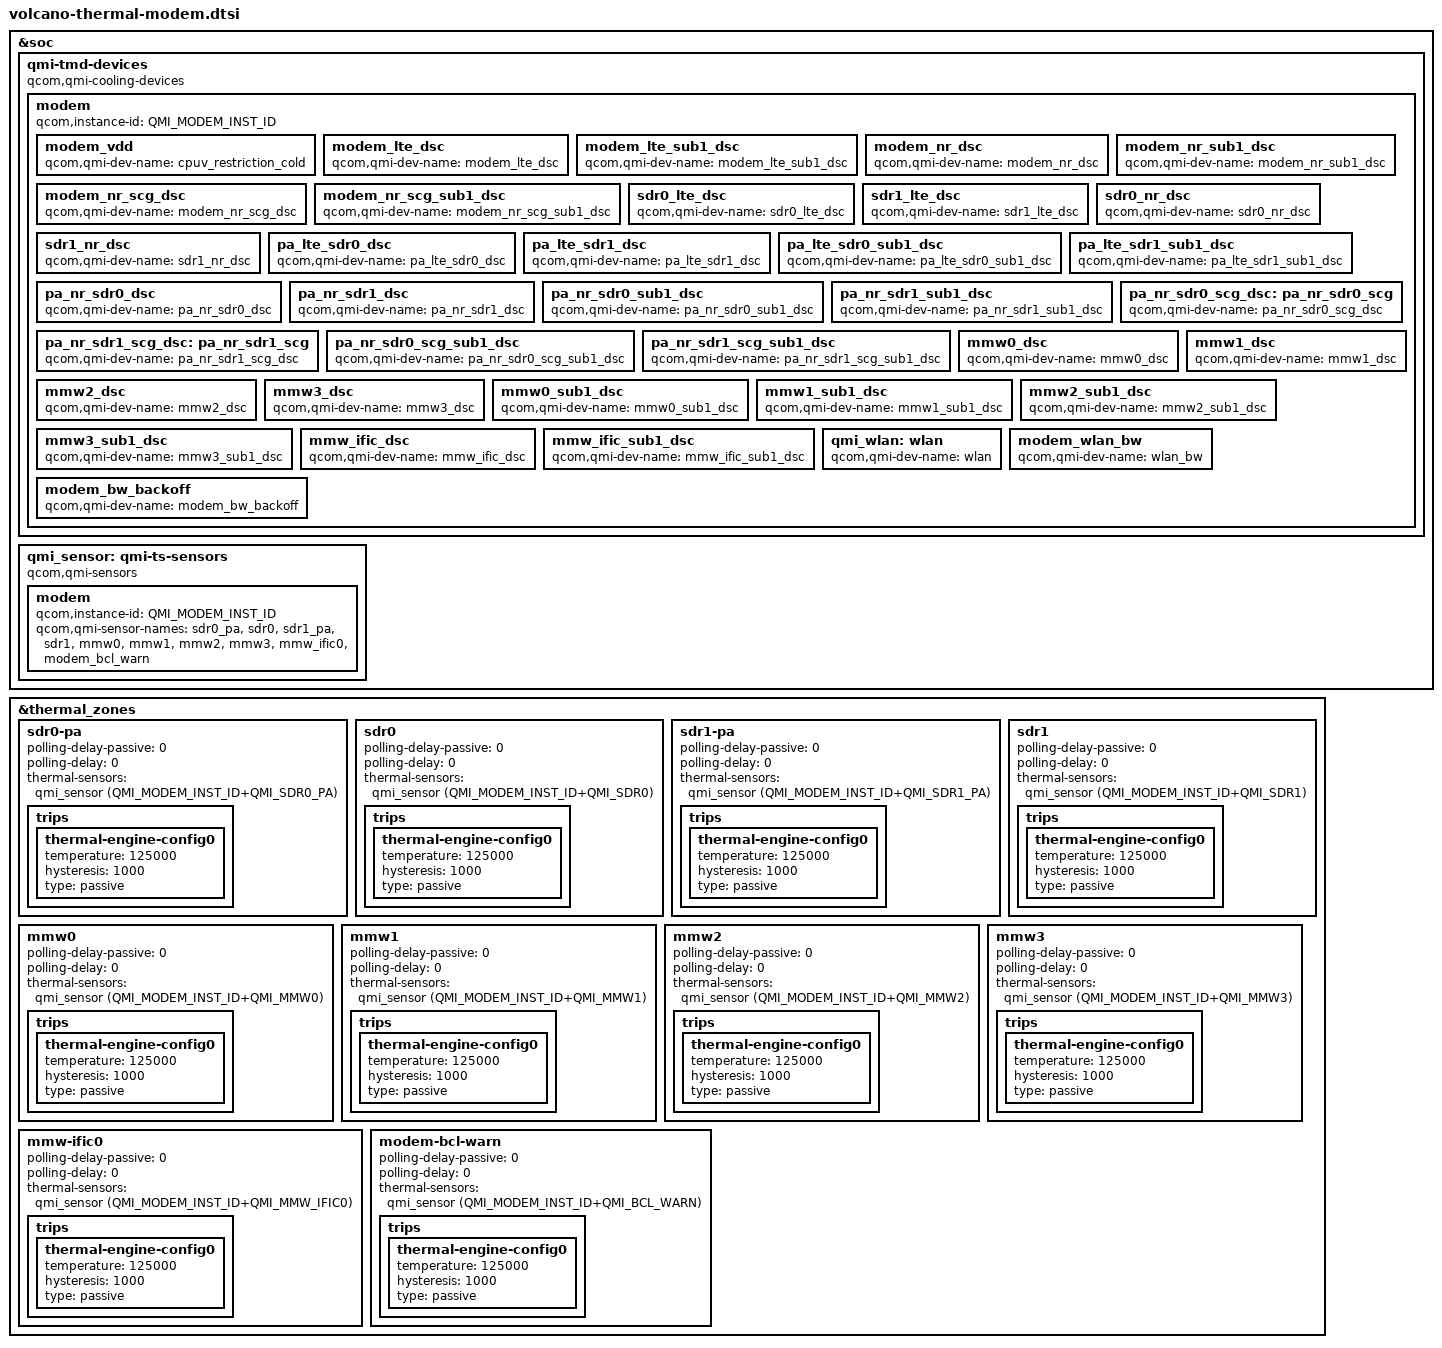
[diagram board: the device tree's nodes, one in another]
#include <dt-bindings/thermal/thermal_qti.h>

&soc {
	qmi-tmd-devices {
	    compatible = "qcom,qmi-cooling-devices";

	    modem {
			qcom,instance-id = <QMI_MODEM_INST_ID>;

			modem_vdd: modem_vdd {
				qcom,qmi-dev-name = "cpuv_restriction_cold";
				#cooling-cells = <2>;
			};

			modem_lte_dsc: modem_lte_dsc {
			    qcom,qmi-dev-name = "modem_lte_dsc";
			    #cooling-cells = <2>;
			};

			modem_lte_sub1_dsc: modem_lte_sub1_dsc {
				qcom,qmi-dev-name = "modem_lte_sub1_dsc";
				#cooling-cells = <2>;
			};

			modem_nr_dsc: modem_nr_dsc {
				qcom,qmi-dev-name = "modem_nr_dsc";
				#cooling-cells = <2>;
			};

			modem_nr_sub1_dsc: modem_nr_sub1_dsc {
				qcom,qmi-dev-name = "modem_nr_sub1_dsc";
				#cooling-cells = <2>;
			};

			modem_nr_scg_dsc: modem_nr_scg_dsc {
				qcom,qmi-dev-name = "modem_nr_scg_dsc";
				#cooling-cells = <2>;
			};

			modem_nr_scg_sub1_dsc: modem_nr_scg_sub1_dsc {
				qcom,qmi-dev-name = "modem_nr_scg_sub1_dsc";
				#cooling-cells = <2>;
			};

			sdr0_lte_dsc: sdr0_lte_dsc {
				qcom,qmi-dev-name = "sdr0_lte_dsc";
				#cooling-cells = <2>;
			};

			sdr1_lte_dsc: sdr1_lte_dsc {
				qcom,qmi-dev-name = "sdr1_lte_dsc";
				#cooling-cells = <2>;
			};

			sdr0_nr_dsc: sdr0_nr_dsc {
				qcom,qmi-dev-name = "sdr0_nr_dsc";
				#cooling-cells = <2>;
			};

			sdr1_nr_dsc: sdr1_nr_dsc {
				qcom,qmi-dev-name = "sdr1_nr_dsc";
				#cooling-cells = <2>;
			};

			pa_lte_sdr0_dsc: pa_lte_sdr0_dsc {
				qcom,qmi-dev-name = "pa_lte_sdr0_dsc";
				#cooling-cells = <2>;
			};

			pa_lte_sdr1_dsc: pa_lte_sdr1_dsc {
				qcom,qmi-dev-name = "pa_lte_sdr1_dsc";
				#cooling-cells = <2>;
			};

			pa_lte_sdr0_sub1_dsc: pa_lte_sdr0_sub1_dsc {
				qcom,qmi-dev-name = "pa_lte_sdr0_sub1_dsc";
				#cooling-cells = <2>;
			};

			pa_lte_sdr1_sub1_dsc: pa_lte_sdr1_sub1_dsc {
				qcom,qmi-dev-name = "pa_lte_sdr1_sub1_dsc";
				#cooling-cells = <2>;
			};

			pa_nr_sdr0_dsc: pa_nr_sdr0_dsc {
				qcom,qmi-dev-name = "pa_nr_sdr0_dsc";
				#cooling-cells = <2>;
			};

			pa_nr_sdr1_dsc: pa_nr_sdr1_dsc {
				qcom,qmi-dev-name = "pa_nr_sdr1_dsc";
				#cooling-cells = <2>;
			};

			pa_nr_sdr0_sub1_dsc: pa_nr_sdr0_sub1_dsc {
				qcom,qmi-dev-name = "pa_nr_sdr0_sub1_dsc";
				#cooling-cells = <2>;
			};

			pa_nr_sdr1_sub1_dsc: pa_nr_sdr1_sub1_dsc {
				qcom,qmi-dev-name = "pa_nr_sdr1_sub1_dsc";
				#cooling-cells = <2>;
			};

			pa_nr_sdr0_scg_dsc: pa_nr_sdr0_scg {
				qcom,qmi-dev-name = "pa_nr_sdr0_scg_dsc";
				#cooling-cells = <2>;
			};

			pa_nr_sdr1_scg_dsc: pa_nr_sdr1_scg {
				qcom,qmi-dev-name = "pa_nr_sdr1_scg_dsc";
				#cooling-cells = <2>;
			};

			pa_nr_sdr0_scg_sub1_dsc: pa_nr_sdr0_scg_sub1_dsc {
				qcom,qmi-dev-name = "pa_nr_sdr0_scg_sub1_dsc";
				#cooling-cells = <2>;
			};

			pa_nr_sdr1_scg_sub1_dsc: pa_nr_sdr1_scg_sub1_dsc {
				qcom,qmi-dev-name = "pa_nr_sdr1_scg_sub1_dsc";
				#cooling-cells = <2>;
			};

			mmw0_dsc: mmw0_dsc {
				qcom,qmi-dev-name = "mmw0_dsc";
				#cooling-cells = <2>;
			};

			mmw1_dsc: mmw1_dsc {
				qcom,qmi-dev-name = "mmw1_dsc";
				#cooling-cells = <2>;
			};

			mmw2_dsc: mmw2_dsc {
				qcom,qmi-dev-name = "mmw2_dsc";
				#cooling-cells = <2>;
			};

			mmw3_dsc: mmw3_dsc {
				qcom,qmi-dev-name = "mmw3_dsc";
				#cooling-cells = <2>;
			};

			mmw0_sub1_dsc: mmw0_sub1_dsc {
				qcom,qmi-dev-name = "mmw0_sub1_dsc";
				#cooling-cells = <2>;
			};

			mmw1_sub1_dsc: mmw1_sub1_dsc {
				qcom,qmi-dev-name = "mmw1_sub1_dsc";
				#cooling-cells = <2>;
			};

			mmw2_sub1_dsc: mmw2_sub1_dsc {
				qcom,qmi-dev-name = "mmw2_sub1_dsc";
				#cooling-cells = <2>;
			};

			mmw3_sub1_dsc: mmw3_sub1_dsc {
					qcom,qmi-dev-name = "mmw3_sub1_dsc";
					#cooling-cells = <2>;
			};

			mmw_ific_dsc: mmw_ific_dsc {
				qcom,qmi-dev-name = "mmw_ific_dsc";
				#cooling-cells = <2>;
			};

			mmw_ific_sub1_dsc: mmw_ific_sub1_dsc {
				qcom,qmi-dev-name = "mmw_ific_sub1_dsc";
				#cooling-cells = <2>;
			};

			qmi_wlan: wlan {
				qcom,qmi-dev-name = "wlan";
				#cooling-cells = <2>;
			};

			modem_wlan_bw: modem_wlan_bw {
				qcom,qmi-dev-name = "wlan_bw";
				#cooling-cells = <2>;
			};

			modem_bw_backoff: modem_bw_backoff {
				qcom,qmi-dev-name = "modem_bw_backoff";
				#cooling-cells = <2>;
			};
		};
	};

	qmi_sensor: qmi-ts-sensors {
		compatible = "qcom,qmi-sensors";
		#thermal-sensor-cells = <1>;

		modem {
			qcom,instance-id = <QMI_MODEM_INST_ID>;
				qcom,qmi-sensor-names = "sdr0_pa",
							"sdr0",
							"sdr1_pa",
							"sdr1",
							"mmw0",
							"mmw1",
							"mmw2",
							"mmw3",
							"mmw_ific0",
							"modem_bcl_warn";
		};
	};
};


&thermal_zones {
	sdr0-pa {
		polling-delay-passive = <0>;
		polling-delay = <0>;
		thermal-sensors = <&qmi_sensor
				(QMI_MODEM_INST_ID+QMI_SDR0_PA)>;
		trips {
			thermal-engine-config0 {
				temperature = <125000>;
				hysteresis = <1000>;
				type = "passive";
			};
		};
	};

	sdr0 {
		polling-delay-passive = <0>;
		polling-delay = <0>;
		thermal-sensors = <&qmi_sensor
				(QMI_MODEM_INST_ID+QMI_SDR0)>;
		trips {
			thermal-engine-config0 {
				temperature = <125000>;
				hysteresis = <1000>;
				type = "passive";
			};
		};
	};

	sdr1-pa {
		polling-delay-passive = <0>;
		polling-delay = <0>;
		thermal-sensors = <&qmi_sensor
				(QMI_MODEM_INST_ID+QMI_SDR1_PA)>;
		trips {
			thermal-engine-config0 {
				temperature = <125000>;
				hysteresis = <1000>;
				type = "passive";
			};
		};
	};

	sdr1 {
		polling-delay-passive = <0>;
		polling-delay = <0>;
		thermal-sensors = <&qmi_sensor
				(QMI_MODEM_INST_ID+QMI_SDR1)>;
		trips {
			thermal-engine-config0 {
				temperature = <125000>;
				hysteresis = <1000>;
				type = "passive";
			};
		};
	};

	mmw0 {
		polling-delay-passive = <0>;
		polling-delay = <0>;
		thermal-sensors = <&qmi_sensor
				(QMI_MODEM_INST_ID+QMI_MMW0)>;
		trips {
			thermal-engine-config0 {
				temperature = <125000>;
				hysteresis = <1000>;
				type = "passive";
			};
		};
	};

	mmw1 {
		polling-delay-passive = <0>;
		polling-delay = <0>;
		thermal-sensors = <&qmi_sensor
				(QMI_MODEM_INST_ID+QMI_MMW1)>;
		trips {
			thermal-engine-config0 {
				temperature = <125000>;
				hysteresis = <1000>;
				type = "passive";
			};
		};
	};

	mmw2 {
		polling-delay-passive = <0>;
		polling-delay = <0>;
		thermal-sensors = <&qmi_sensor
				(QMI_MODEM_INST_ID+QMI_MMW2)>;
		trips {
			thermal-engine-config0 {
				temperature = <125000>;
				hysteresis = <1000>;
				type = "passive";
			};
	    };
	};

	mmw3 {
		polling-delay-passive = <0>;
		polling-delay = <0>;
		thermal-sensors = <&qmi_sensor
				(QMI_MODEM_INST_ID+QMI_MMW3)>;
		trips {
			thermal-engine-config0 {
				temperature = <125000>;
				hysteresis = <1000>;
				type = "passive";
			};
		};
	};

	mmw-ific0 {
		polling-delay-passive = <0>;
		polling-delay = <0>;
		thermal-sensors = <&qmi_sensor
				(QMI_MODEM_INST_ID+QMI_MMW_IFIC0)>;
		trips {
			thermal-engine-config0 {
				temperature = <125000>;
				hysteresis = <1000>;
				type = "passive";
			};
		};
	};

	modem-bcl-warn {
		polling-delay-passive = <0>;
		polling-delay = <0>;
		thermal-sensors = <&qmi_sensor
				(QMI_MODEM_INST_ID+QMI_BCL_WARN)>;
		trips {
			thermal-engine-config0 {
				temperature = <125000>;
				hysteresis = <1000>;
				type = "passive";
			};
		};
	};
};
